# CC3200 register map
Vendor: Texas Instruments; Series: SimpleLink; File version: 1.0
CPU: CM4 r0p1, little endian, MPU, no FPU, 3 interrupt priority bits
Registers are 32-bit, read-write, reset 0x0 unless marked. A register's access mark holds for its fields unless they carry their own. Offsets are from the block's base; [hi:lo] are bit positions.

## HIB1P2
Base 0x4402F000
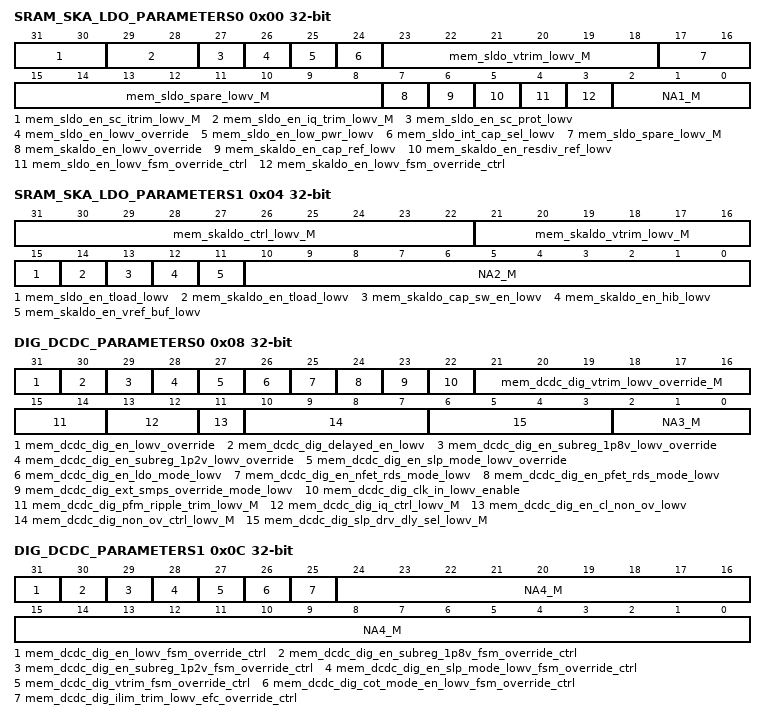
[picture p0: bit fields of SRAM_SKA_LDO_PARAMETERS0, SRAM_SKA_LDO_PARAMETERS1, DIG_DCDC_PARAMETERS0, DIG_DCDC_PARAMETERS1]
0x00 SRAM_SKA_LDO_PARAMETERS0 — HIB1P2_SRAM_SKA_LDO_PARAMETERS0
  [31:30] mem_sldo_en_sc_itrim_lowv_M — HIB1P2_SRAM_SKA_LDO_PARAMETERS0
  [29:28] mem_sldo_en_iq_trim_lowv_M — HIB1P2_SRAM_SKA_LDO_PARAMETERS0
  [27] mem_sldo_en_sc_prot_lowv — HIB1P2_SRAM_SKA_LDO_PARAMETERS0
  [26] mem_sldo_en_lowv_override — HIB1P2_SRAM_SKA_LDO_PARAMETERS0
  [25] mem_sldo_en_low_pwr_lowv — HIB1P2_SRAM_SKA_LDO_PARAMETERS0
  [24] mem_sldo_int_cap_sel_lowv — HIB1P2_SRAM_SKA_LDO_PARAMETERS0
  [23:18] mem_sldo_vtrim_lowv_M — HIB1P2_SRAM_SKA_LDO_PARAMETERS0
  [17:8] mem_sldo_spare_lowv_M — HIB1P2_SRAM_SKA_LDO_PARAMETERS0
  [7] mem_skaldo_en_lowv_override — HIB1P2_SRAM_SKA_LDO_PARAMETERS0
  [6] mem_skaldo_en_cap_ref_lowv — HIB1P2_SRAM_SKA_LDO_PARAMETERS0
  [5] mem_skaldo_en_resdiv_ref_lowv — HIB1P2_SRAM_SKA_LDO_PARAMETERS0
  [4] mem_sldo_en_lowv_fsm_override_ctrl — HIB1P2_SRAM_SKA_LDO_PARAMETERS0
  [3] mem_skaldo_en_lowv_fsm_override_ctrl — HIB1P2_SRAM_SKA_LDO_PARAMETERS0
  [2:0] NA1_M — HIB1P2_SRAM_SKA_LDO_PARAMETERS0
0x04 SRAM_SKA_LDO_PARAMETERS1 — HIB1P2_SRAM_SKA_LDO_PARAMETERS1
  [31:22] mem_skaldo_ctrl_lowv_M — HIB1P2_SRAM_SKA_LDO_PARAMETERS1
  [21:16] mem_skaldo_vtrim_lowv_M — HIB1P2_SRAM_SKA_LDO_PARAMETERS1
  [15] mem_sldo_en_tload_lowv — HIB1P2_SRAM_SKA_LDO_PARAMETERS1
  [14] mem_skaldo_en_tload_lowv — HIB1P2_SRAM_SKA_LDO_PARAMETERS1
  [13] mem_skaldo_cap_sw_en_lowv — HIB1P2_SRAM_SKA_LDO_PARAMETERS1
  [12] mem_skaldo_en_hib_lowv — HIB1P2_SRAM_SKA_LDO_PARAMETERS1
  [11] mem_skaldo_en_vref_buf_lowv — HIB1P2_SRAM_SKA_LDO_PARAMETERS1
  [10:0] NA2_M — HIB1P2_SRAM_SKA_LDO_PARAMETERS1
0x08 DIG_DCDC_PARAMETERS0 — HIB1P2_DIG_DCDC_PARAMETERS0
  [31] mem_dcdc_dig_en_lowv_override — HIB1P2_DIG_DCDC_PARAMETERS0
  [30] mem_dcdc_dig_delayed_en_lowv — HIB1P2_DIG_DCDC_PARAMETERS0
  [29] mem_dcdc_dig_en_subreg_1p8v_lowv_override — HIB1P2_DIG_DCDC_PARAMETERS0
  [28] mem_dcdc_dig_en_subreg_1p2v_lowv_override — HIB1P2_DIG_DCDC_PARAMETERS0
  [27] mem_dcdc_dig_en_slp_mode_lowv_override — HIB1P2_DIG_DCDC_PARAMETERS0
  [26] mem_dcdc_dig_en_ldo_mode_lowv — HIB1P2_DIG_DCDC_PARAMETERS0
  [25] mem_dcdc_dig_en_nfet_rds_mode_lowv — HIB1P2_DIG_DCDC_PARAMETERS0
  [24] mem_dcdc_dig_en_pfet_rds_mode_lowv — HIB1P2_DIG_DCDC_PARAMETERS0
  [23] mem_dcdc_dig_ext_smps_override_mode_lowv — HIB1P2_DIG_DCDC_PARAMETERS0
  [22] mem_dcdc_dig_clk_in_lowv_enable — HIB1P2_DIG_DCDC_PARAMETERS0
  [21:16] mem_dcdc_dig_vtrim_lowv_override_M — HIB1P2_DIG_DCDC_PARAMETERS0
  [15:14] mem_dcdc_dig_pfm_ripple_trim_lowv_M — HIB1P2_DIG_DCDC_PARAMETERS0
  [13:12] mem_dcdc_dig_iq_ctrl_lowv_M — HIB1P2_DIG_DCDC_PARAMETERS0
  [11] mem_dcdc_dig_en_cl_non_ov_lowv — HIB1P2_DIG_DCDC_PARAMETERS0
  [10:7] mem_dcdc_dig_non_ov_ctrl_lowv_M — HIB1P2_DIG_DCDC_PARAMETERS0
  [6:3] mem_dcdc_dig_slp_drv_dly_sel_lowv_M — HIB1P2_DIG_DCDC_PARAMETERS0
  [2:0] NA3_M — HIB1P2_DIG_DCDC_PARAMETERS0
0x0C DIG_DCDC_PARAMETERS1 — HIB1P2_DIG_DCDC_PARAMETERS1
  [31] mem_dcdc_dig_en_lowv_fsm_override_ctrl — HIB1P2_DIG_DCDC_PARAMETERS1
  [30] mem_dcdc_dig_en_subreg_1p8v_fsm_override_ctrl — HIB1P2_DIG_DCDC_PARAMETERS1
  [29] mem_dcdc_dig_en_subreg_1p2v_fsm_override_ctrl — HIB1P2_DIG_DCDC_PARAMETERS1
  [28] mem_dcdc_dig_en_slp_mode_lowv_fsm_override_ctrl — HIB1P2_DIG_DCDC_PARAMETERS1
  [27] mem_dcdc_dig_vtrim_fsm_override_ctrl — HIB1P2_DIG_DCDC_PARAMETERS1
  [26] mem_dcdc_dig_cot_mode_en_lowv_fsm_override_ctrl — HIB1P2_DIG_DCDC_PARAMETERS1
  [25] mem_dcdc_dig_ilim_trim_lowv_efc_override_ctrl — HIB1P2_DIG_DCDC_PARAMETERS1
  [24:0] NA4_M — HIB1P2_DIG_DCDC_PARAMETERS1
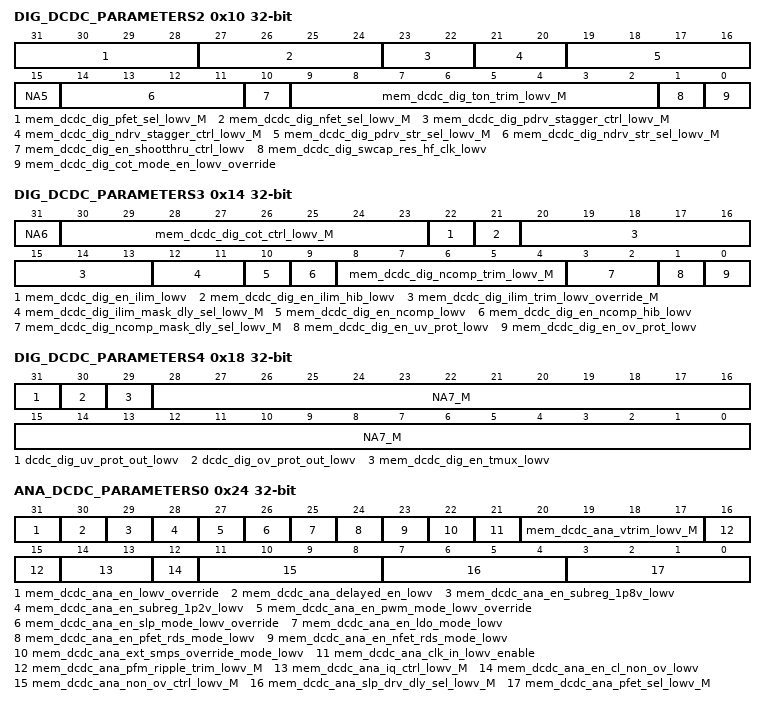
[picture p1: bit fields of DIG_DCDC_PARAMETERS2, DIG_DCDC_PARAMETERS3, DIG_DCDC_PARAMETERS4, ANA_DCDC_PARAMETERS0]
0x10 DIG_DCDC_PARAMETERS2 — HIB1P2_DIG_DCDC_PARAMETERS2
  [31:28] mem_dcdc_dig_pfet_sel_lowv_M — HIB1P2_DIG_DCDC_PARAMETERS2
  [27:24] mem_dcdc_dig_nfet_sel_lowv_M — HIB1P2_DIG_DCDC_PARAMETERS2
  [23:22] mem_dcdc_dig_pdrv_stagger_ctrl_lowv_M — HIB1P2_DIG_DCDC_PARAMETERS2
  [21:20] mem_dcdc_dig_ndrv_stagger_ctrl_lowv_M — HIB1P2_DIG_DCDC_PARAMETERS2
  [19:16] mem_dcdc_dig_pdrv_str_sel_lowv_M — HIB1P2_DIG_DCDC_PARAMETERS2
  [15] NA5 — HIB1P2_DIG_DCDC_PARAMETERS2
  [14:11] mem_dcdc_dig_ndrv_str_sel_lowv_M — HIB1P2_DIG_DCDC_PARAMETERS2
  [10] mem_dcdc_dig_en_shootthru_ctrl_lowv — HIB1P2_DIG_DCDC_PARAMETERS2
  [9:2] mem_dcdc_dig_ton_trim_lowv_M — HIB1P2_DIG_DCDC_PARAMETERS2
  [1] mem_dcdc_dig_swcap_res_hf_clk_lowv — HIB1P2_DIG_DCDC_PARAMETERS2
  [0] mem_dcdc_dig_cot_mode_en_lowv_override — HIB1P2_DIG_DCDC_PARAMETERS2
0x14 DIG_DCDC_PARAMETERS3 — HIB1P2_DIG_DCDC_PARAMETERS3
  [31] NA6 — HIB1P2_DIG_DCDC_PARAMETERS3
  [30:23] mem_dcdc_dig_cot_ctrl_lowv_M — HIB1P2_DIG_DCDC_PARAMETERS3
  [22] mem_dcdc_dig_en_ilim_lowv — HIB1P2_DIG_DCDC_PARAMETERS3
  [21] mem_dcdc_dig_en_ilim_hib_lowv — HIB1P2_DIG_DCDC_PARAMETERS3
  [20:13] mem_dcdc_dig_ilim_trim_lowv_override_M — HIB1P2_DIG_DCDC_PARAMETERS3
  [12:11] mem_dcdc_dig_ilim_mask_dly_sel_lowv_M — HIB1P2_DIG_DCDC_PARAMETERS3
  [10] mem_dcdc_dig_en_ncomp_lowv — HIB1P2_DIG_DCDC_PARAMETERS3
  [9] mem_dcdc_dig_en_ncomp_hib_lowv — HIB1P2_DIG_DCDC_PARAMETERS3
  [8:4] mem_dcdc_dig_ncomp_trim_lowv_M — HIB1P2_DIG_DCDC_PARAMETERS3
  [3:2] mem_dcdc_dig_ncomp_mask_dly_sel_lowv_M — HIB1P2_DIG_DCDC_PARAMETERS3
  [1] mem_dcdc_dig_en_uv_prot_lowv — HIB1P2_DIG_DCDC_PARAMETERS3
  [0] mem_dcdc_dig_en_ov_prot_lowv — HIB1P2_DIG_DCDC_PARAMETERS3
0x18 DIG_DCDC_PARAMETERS4 — HIB1P2_DIG_DCDC_PARAMETERS4
  [31] dcdc_dig_uv_prot_out_lowv — HIB1P2_DIG_DCDC_PARAMETERS4
  [30] dcdc_dig_ov_prot_out_lowv — HIB1P2_DIG_DCDC_PARAMETERS4
  [29] mem_dcdc_dig_en_tmux_lowv — HIB1P2_DIG_DCDC_PARAMETERS4
  [28:0] NA7_M — HIB1P2_DIG_DCDC_PARAMETERS4
0x1C DIG_DCDC_PARAMETERS5 — HIB1P2_DIG_DCDC_PARAMETERS5
  [31:0] mem_dcdc_dig_tmux_ctrl_lowv_M
0x20 DIG_DCDC_PARAMETERS6 — HIB1P2_DIG_DCDC_PARAMETERS6
  [31:0] mem_dcdc_dig_spare_lowv_M
0x24 ANA_DCDC_PARAMETERS0 — HIB1P2_ANA_DCDC_PARAMETERS0
  [31] mem_dcdc_ana_en_lowv_override — HIB1P2_ANA_DCDC_PARAMETERS0
  [30] mem_dcdc_ana_delayed_en_lowv — HIB1P2_ANA_DCDC_PARAMETERS0
  [29] mem_dcdc_ana_en_subreg_1p8v_lowv — HIB1P2_ANA_DCDC_PARAMETERS0
  [28] mem_dcdc_ana_en_subreg_1p2v_lowv — HIB1P2_ANA_DCDC_PARAMETERS0
  [27] mem_dcdc_ana_en_pwm_mode_lowv_override — HIB1P2_ANA_DCDC_PARAMETERS0
  [26] mem_dcdc_ana_en_slp_mode_lowv_override — HIB1P2_ANA_DCDC_PARAMETERS0
  [25] mem_dcdc_ana_en_ldo_mode_lowv — HIB1P2_ANA_DCDC_PARAMETERS0
  [24] mem_dcdc_ana_en_pfet_rds_mode_lowv — HIB1P2_ANA_DCDC_PARAMETERS0
  [23] mem_dcdc_ana_en_nfet_rds_mode_lowv — HIB1P2_ANA_DCDC_PARAMETERS0
  [22] mem_dcdc_ana_ext_smps_override_mode_lowv — HIB1P2_ANA_DCDC_PARAMETERS0
  [21] mem_dcdc_ana_clk_in_lowv_enable — HIB1P2_ANA_DCDC_PARAMETERS0
  [20:17] mem_dcdc_ana_vtrim_lowv_M — HIB1P2_ANA_DCDC_PARAMETERS0
  [16:15] mem_dcdc_ana_pfm_ripple_trim_lowv_M — HIB1P2_ANA_DCDC_PARAMETERS0
  [14:13] mem_dcdc_ana_iq_ctrl_lowv_M — HIB1P2_ANA_DCDC_PARAMETERS0
  [12] mem_dcdc_ana_en_cl_non_ov_lowv — HIB1P2_ANA_DCDC_PARAMETERS0
  [11:8] mem_dcdc_ana_non_ov_ctrl_lowv_M — HIB1P2_ANA_DCDC_PARAMETERS0
  [7:4] mem_dcdc_ana_slp_drv_dly_sel_lowv_M — HIB1P2_ANA_DCDC_PARAMETERS0
  [3:0] mem_dcdc_ana_pfet_sel_lowv_M — HIB1P2_ANA_DCDC_PARAMETERS0
0x28 ANA_DCDC_PARAMETERS1 — HIB1P2_ANA_DCDC_PARAMETERS1
  [31] _dcdc_ana_ov_prot_out_lowv — HIB1P2_ANA_DCDC_PARAMETERS1
  [30] _mem_dcdc_ana_en_tmux_lowv — HIB1P2_ANA_DCDC_PARAMETERS1
  [31:28] mem_dcdc_ana_nfet_sel_lowv_M — HIB1P2_ANA_DCDC_PARAMETERS1
  [27:26] mem_dcdc_ana_pdrv_stagger_ctrl_lowv_M — HIB1P2_ANA_DCDC_PARAMETERS1
  [25:24] mem_dcdc_ana_ndrv_stagger_ctrl_lowv_M — HIB1P2_ANA_DCDC_PARAMETERS1
  [21] _mem_dcdc_ana_en_ilim_lowv — HIB1P2_ANA_DCDC_PARAMETERS1
  [23:20] mem_dcdc_ana_pdrv_str_sel_lowv_M — HIB1P2_ANA_DCDC_PARAMETERS1
  [20] _mem_dcdc_ana_en_ilim_hib_lowv — HIB1P2_ANA_DCDC_PARAMETERS1
  [19:16] mem_dcdc_ana_ndrv_str_sel_lowv_M — HIB1P2_ANA_DCDC_PARAMETERS1
  [15] mem_dcdc_ana_en_rtrim_lowv — HIB1P2_ANA_DCDC_PARAMETERS1
  [14] mem_dcdc_ana_apwm_en_lowv — HIB1P2_ANA_DCDC_PARAMETERS1
  [19:12] _mem_dcdc_ana_ilim_trim_lowv_override_M — HIB1P2_ANA_DCDC_PARAMETERS1
  [11:10] _mem_dcdc_ana_ilim_mask_dly_sel_lowv_M — HIB1P2_ANA_DCDC_PARAMETERS1
  [13:9] mem_dcdc_ana_ramp_hgt_lowv_M — HIB1P2_ANA_DCDC_PARAMETERS1
  [9] _mem_dcdc_ana_en_ncomp_lowv — HIB1P2_ANA_DCDC_PARAMETERS1
  [8] mem_dcdc_ana_en_anti_glitch_lowv — HIB1P2_ANA_DCDC_PARAMETERS1
  [8] _mem_dcdc_ana_en_ncomp_hib_lowv — HIB1P2_ANA_DCDC_PARAMETERS1
  [7] mem_dcdc_ana_en_hi_clamp_lowv — HIB1P2_ANA_DCDC_PARAMETERS1
  [6:5] mem_dcdc_ana_hi_clamp_trim_lowv_M — HIB1P2_ANA_DCDC_PARAMETERS1
  [4] mem_dcdc_ana_en_lo_clamp_lowv — HIB1P2_ANA_DCDC_PARAMETERS1
  [7:3] _mem_dcdc_ana_ncomp_trim_lowv_M — HIB1P2_ANA_DCDC_PARAMETERS1
  [3:2] mem_dcdc_ana_lo_clamp_trim_lowv_M — HIB1P2_ANA_DCDC_PARAMETERS1
  [2:1] _mem_dcdc_ana_ncomp_mask_dly_sel_lowv_M — HIB1P2_ANA_DCDC_PARAMETERS1
  [1:0] NA8_M — HIB1P2_ANA_DCDC_PARAMETERS1
  [0] _mem_dcdc_ana_en_ov_prot_lowv — HIB1P2_ANA_DCDC_PARAMETERS1
  [29:0] _NA17_M — HIB1P2_ANA_DCDC_PARAMETERS1
  [31:0] _mem_dcdc_ana_tmux_ctrl_lowv_M — HIB1P2_ANA_DCDC_PARAMETERS1
  [31:0] _mem_dcdc_ana_spare_lowv_M — HIB1P2_ANA_DCDC_PARAMETERS1
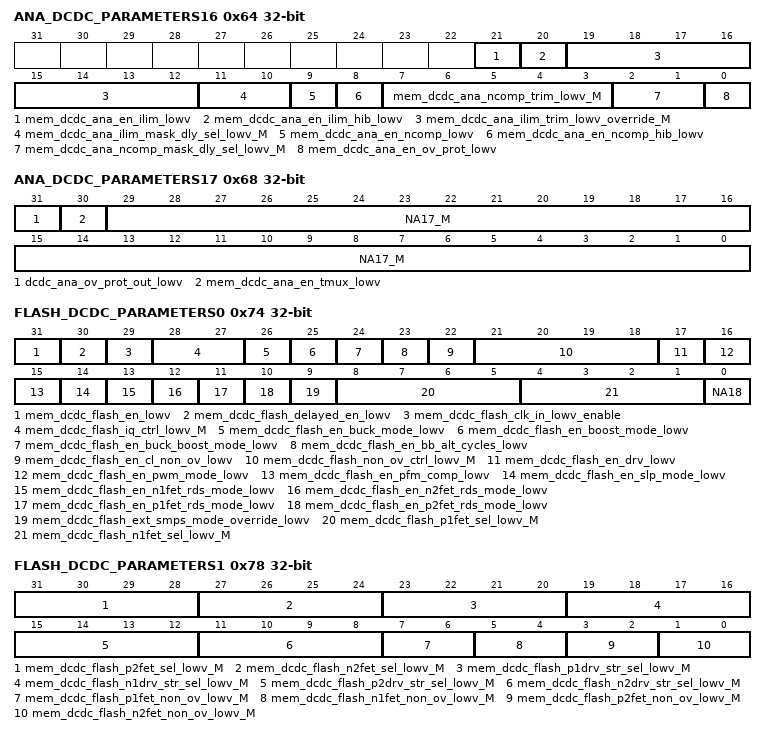
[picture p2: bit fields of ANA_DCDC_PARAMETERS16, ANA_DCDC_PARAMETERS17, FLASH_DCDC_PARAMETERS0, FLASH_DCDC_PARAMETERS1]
0x64 ANA_DCDC_PARAMETERS16 — HIB1P2_ANA_DCDC_PARAMETERS16
  [21] mem_dcdc_ana_en_ilim_lowv — HIB1P2_ANA_DCDC_PARAMETERS16
  [20] mem_dcdc_ana_en_ilim_hib_lowv — HIB1P2_ANA_DCDC_PARAMETERS16
  [19:12] mem_dcdc_ana_ilim_trim_lowv_override_M — HIB1P2_ANA_DCDC_PARAMETERS16
  [11:10] mem_dcdc_ana_ilim_mask_dly_sel_lowv_M — HIB1P2_ANA_DCDC_PARAMETERS16
  [9] mem_dcdc_ana_en_ncomp_lowv — HIB1P2_ANA_DCDC_PARAMETERS16
  [8] mem_dcdc_ana_en_ncomp_hib_lowv — HIB1P2_ANA_DCDC_PARAMETERS16
  [7:3] mem_dcdc_ana_ncomp_trim_lowv_M — HIB1P2_ANA_DCDC_PARAMETERS16
  [2:1] mem_dcdc_ana_ncomp_mask_dly_sel_lowv_M — HIB1P2_ANA_DCDC_PARAMETERS16
  [0] mem_dcdc_ana_en_ov_prot_lowv — HIB1P2_ANA_DCDC_PARAMETERS16
0x68 ANA_DCDC_PARAMETERS17 — HIB1P2_ANA_DCDC_PARAMETERS17
  [31] dcdc_ana_ov_prot_out_lowv — HIB1P2_ANA_DCDC_PARAMETERS17
  [30] mem_dcdc_ana_en_tmux_lowv — HIB1P2_ANA_DCDC_PARAMETERS17
  [29:0] NA17_M — HIB1P2_ANA_DCDC_PARAMETERS17
0x6C ANA_DCDC_PARAMETERS18 — HIB1P2_ANA_DCDC_PARAMETERS18
  [31:0] mem_dcdc_ana_tmux_ctrl_lowv_M
0x70 ANA_DCDC_PARAMETERS19 — HIB1P2_ANA_DCDC_PARAMETERS19
  [31:0] mem_dcdc_ana_spare_lowv_M
0x74 FLASH_DCDC_PARAMETERS0 — HIB1P2_FLASH_DCDC_PARAMETERS0
  [31] mem_dcdc_flash_en_lowv — HIB1P2_FLASH_DCDC_PARAMETERS0
  [30] mem_dcdc_flash_delayed_en_lowv — HIB1P2_FLASH_DCDC_PARAMETERS0
  [29] mem_dcdc_flash_clk_in_lowv_enable — HIB1P2_FLASH_DCDC_PARAMETERS0
  [28:27] mem_dcdc_flash_iq_ctrl_lowv_M — HIB1P2_FLASH_DCDC_PARAMETERS0
  [26] mem_dcdc_flash_en_buck_mode_lowv — HIB1P2_FLASH_DCDC_PARAMETERS0
  [25] mem_dcdc_flash_en_boost_mode_lowv — HIB1P2_FLASH_DCDC_PARAMETERS0
  [24] mem_dcdc_flash_en_buck_boost_mode_lowv — HIB1P2_FLASH_DCDC_PARAMETERS0
  [23] mem_dcdc_flash_en_bb_alt_cycles_lowv — HIB1P2_FLASH_DCDC_PARAMETERS0
  [22] mem_dcdc_flash_en_cl_non_ov_lowv — HIB1P2_FLASH_DCDC_PARAMETERS0
  [21:18] mem_dcdc_flash_non_ov_ctrl_lowv_M — HIB1P2_FLASH_DCDC_PARAMETERS0
  [17] mem_dcdc_flash_en_drv_lowv — HIB1P2_FLASH_DCDC_PARAMETERS0
  [16] mem_dcdc_flash_en_pwm_mode_lowv — HIB1P2_FLASH_DCDC_PARAMETERS0
  [15] mem_dcdc_flash_en_pfm_comp_lowv — HIB1P2_FLASH_DCDC_PARAMETERS0
  [14] mem_dcdc_flash_en_slp_mode_lowv — HIB1P2_FLASH_DCDC_PARAMETERS0
  [13] mem_dcdc_flash_en_n1fet_rds_mode_lowv — HIB1P2_FLASH_DCDC_PARAMETERS0
  [12] mem_dcdc_flash_en_n2fet_rds_mode_lowv — HIB1P2_FLASH_DCDC_PARAMETERS0
  [11] mem_dcdc_flash_en_p1fet_rds_mode_lowv — HIB1P2_FLASH_DCDC_PARAMETERS0
  [10] mem_dcdc_flash_en_p2fet_rds_mode_lowv — HIB1P2_FLASH_DCDC_PARAMETERS0
  [9] mem_dcdc_flash_ext_smps_mode_override_lowv — HIB1P2_FLASH_DCDC_PARAMETERS0
  [8:5] mem_dcdc_flash_p1fet_sel_lowv_M — HIB1P2_FLASH_DCDC_PARAMETERS0
  [4:1] mem_dcdc_flash_n1fet_sel_lowv_M — HIB1P2_FLASH_DCDC_PARAMETERS0
  [0] NA18 — HIB1P2_FLASH_DCDC_PARAMETERS0
0x78 FLASH_DCDC_PARAMETERS1 — HIB1P2_FLASH_DCDC_PARAMETERS1
  [31:28] mem_dcdc_flash_p2fet_sel_lowv_M — HIB1P2_FLASH_DCDC_PARAMETERS1
  [27:24] mem_dcdc_flash_n2fet_sel_lowv_M — HIB1P2_FLASH_DCDC_PARAMETERS1
  [23:20] mem_dcdc_flash_p1drv_str_sel_lowv_M — HIB1P2_FLASH_DCDC_PARAMETERS1
  [19:16] mem_dcdc_flash_n1drv_str_sel_lowv_M — HIB1P2_FLASH_DCDC_PARAMETERS1
  [15:12] mem_dcdc_flash_p2drv_str_sel_lowv_M — HIB1P2_FLASH_DCDC_PARAMETERS1
  [11:8] mem_dcdc_flash_n2drv_str_sel_lowv_M — HIB1P2_FLASH_DCDC_PARAMETERS1
  [7:6] mem_dcdc_flash_p1fet_non_ov_lowv_M — HIB1P2_FLASH_DCDC_PARAMETERS1
  [5:4] mem_dcdc_flash_n1fet_non_ov_lowv_M — HIB1P2_FLASH_DCDC_PARAMETERS1
  [3:2] mem_dcdc_flash_p2fet_non_ov_lowv_M — HIB1P2_FLASH_DCDC_PARAMETERS1
  [1:0] mem_dcdc_flash_n2fet_non_ov_lowv_M — HIB1P2_FLASH_DCDC_PARAMETERS1
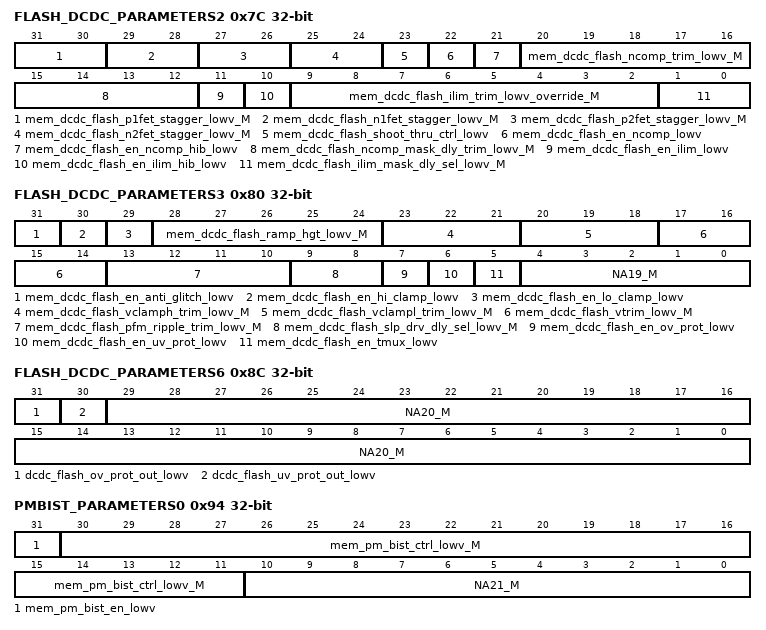
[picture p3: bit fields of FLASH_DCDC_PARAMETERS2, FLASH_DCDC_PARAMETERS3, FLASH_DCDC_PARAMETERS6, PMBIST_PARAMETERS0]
0x7C FLASH_DCDC_PARAMETERS2 — HIB1P2_FLASH_DCDC_PARAMETERS2
  [31:30] mem_dcdc_flash_p1fet_stagger_lowv_M — HIB1P2_FLASH_DCDC_PARAMETERS2
  [29:28] mem_dcdc_flash_n1fet_stagger_lowv_M — HIB1P2_FLASH_DCDC_PARAMETERS2
  [27:26] mem_dcdc_flash_p2fet_stagger_lowv_M — HIB1P2_FLASH_DCDC_PARAMETERS2
  [25:24] mem_dcdc_flash_n2fet_stagger_lowv_M — HIB1P2_FLASH_DCDC_PARAMETERS2
  [23] mem_dcdc_flash_shoot_thru_ctrl_lowv — HIB1P2_FLASH_DCDC_PARAMETERS2
  [22] mem_dcdc_flash_en_ncomp_lowv — HIB1P2_FLASH_DCDC_PARAMETERS2
  [21] mem_dcdc_flash_en_ncomp_hib_lowv — HIB1P2_FLASH_DCDC_PARAMETERS2
  [20:16] mem_dcdc_flash_ncomp_trim_lowv_M — HIB1P2_FLASH_DCDC_PARAMETERS2
  [15:12] mem_dcdc_flash_ncomp_mask_dly_trim_lowv_M — HIB1P2_FLASH_DCDC_PARAMETERS2
  [11] mem_dcdc_flash_en_ilim_lowv — HIB1P2_FLASH_DCDC_PARAMETERS2
  [10] mem_dcdc_flash_en_ilim_hib_lowv — HIB1P2_FLASH_DCDC_PARAMETERS2
  [9:2] mem_dcdc_flash_ilim_trim_lowv_override_M — HIB1P2_FLASH_DCDC_PARAMETERS2
  [1:0] mem_dcdc_flash_ilim_mask_dly_sel_lowv_M — HIB1P2_FLASH_DCDC_PARAMETERS2
0x80 FLASH_DCDC_PARAMETERS3 — HIB1P2_FLASH_DCDC_PARAMETERS3
  [31] mem_dcdc_flash_en_anti_glitch_lowv — HIB1P2_FLASH_DCDC_PARAMETERS3
  [30] mem_dcdc_flash_en_hi_clamp_lowv — HIB1P2_FLASH_DCDC_PARAMETERS3
  [29] mem_dcdc_flash_en_lo_clamp_lowv — HIB1P2_FLASH_DCDC_PARAMETERS3
  [28:24] mem_dcdc_flash_ramp_hgt_lowv_M — HIB1P2_FLASH_DCDC_PARAMETERS3
  [23:21] mem_dcdc_flash_vclamph_trim_lowv_M — HIB1P2_FLASH_DCDC_PARAMETERS3
  [20:18] mem_dcdc_flash_vclampl_trim_lowv_M — HIB1P2_FLASH_DCDC_PARAMETERS3
  [17:14] mem_dcdc_flash_vtrim_lowv_M — HIB1P2_FLASH_DCDC_PARAMETERS3
  [13:10] mem_dcdc_flash_pfm_ripple_trim_lowv_M — HIB1P2_FLASH_DCDC_PARAMETERS3
  [9:8] mem_dcdc_flash_slp_drv_dly_sel_lowv_M — HIB1P2_FLASH_DCDC_PARAMETERS3
  [7] mem_dcdc_flash_en_ov_prot_lowv — HIB1P2_FLASH_DCDC_PARAMETERS3
  [6] mem_dcdc_flash_en_uv_prot_lowv — HIB1P2_FLASH_DCDC_PARAMETERS3
  [5] mem_dcdc_flash_en_tmux_lowv — HIB1P2_FLASH_DCDC_PARAMETERS3
  [4:0] NA19_M — HIB1P2_FLASH_DCDC_PARAMETERS3
0x84 FLASH_DCDC_PARAMETERS4 — HIB1P2_FLASH_DCDC_PARAMETERS4
  [31:0] mem_dcdc_flash_tmux_ctrl_lowv_M
0x88 FLASH_DCDC_PARAMETERS5 — HIB1P2_FLASH_DCDC_PARAMETERS5
  [31:0] mem_dcdc_flash_spare_lowv_M
0x8C FLASH_DCDC_PARAMETERS6 — HIB1P2_FLASH_DCDC_PARAMETERS6
  [31] dcdc_flash_ov_prot_out_lowv — HIB1P2_FLASH_DCDC_PARAMETERS6
  [30] dcdc_flash_uv_prot_out_lowv — HIB1P2_FLASH_DCDC_PARAMETERS6
  [29:0] NA20_M — HIB1P2_FLASH_DCDC_PARAMETERS6
0x94 PMBIST_PARAMETERS0 — HIB1P2_PMBIST_PARAMETERS0
  [31] mem_pm_bist_en_lowv — HIB1P2_PMBIST_PARAMETERS0
  [30:11] mem_pm_bist_ctrl_lowv_M — HIB1P2_PMBIST_PARAMETERS0
  [10:0] NA21_M — HIB1P2_PMBIST_PARAMETERS0
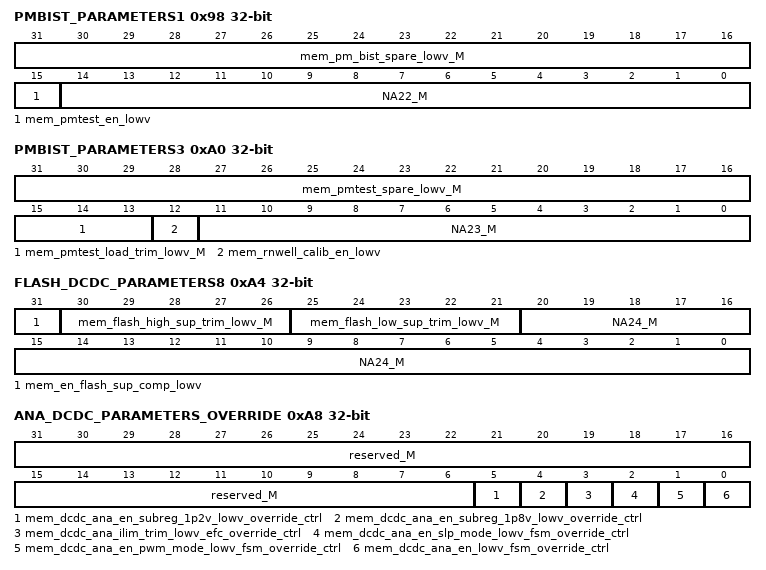
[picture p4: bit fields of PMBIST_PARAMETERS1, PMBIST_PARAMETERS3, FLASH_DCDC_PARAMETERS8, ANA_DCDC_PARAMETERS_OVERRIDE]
0x98 PMBIST_PARAMETERS1 — HIB1P2_PMBIST_PARAMETERS1
  [31:16] mem_pm_bist_spare_lowv_M — HIB1P2_PMBIST_PARAMETERS1
  [15] mem_pmtest_en_lowv — HIB1P2_PMBIST_PARAMETERS1
  [14:0] NA22_M — HIB1P2_PMBIST_PARAMETERS1
0x9C PMBIST_PARAMETERS2 — HIB1P2_PMBIST_PARAMETERS2
  [31:0] mem_pmtest_tmux_ctrl_lowv_M
0xA0 PMBIST_PARAMETERS3 — HIB1P2_PMBIST_PARAMETERS3
  [31:16] mem_pmtest_spare_lowv_M — HIB1P2_PMBIST_PARAMETERS3
  [15:13] mem_pmtest_load_trim_lowv_M — HIB1P2_PMBIST_PARAMETERS3
  [12] mem_rnwell_calib_en_lowv — HIB1P2_PMBIST_PARAMETERS3
  [11:0] NA23_M — HIB1P2_PMBIST_PARAMETERS3
0xA4 FLASH_DCDC_PARAMETERS8 — HIB1P2_FLASH_DCDC_PARAMETERS8
  [31] mem_en_flash_sup_comp_lowv — HIB1P2_FLASH_DCDC_PARAMETERS8
  [30:26] mem_flash_high_sup_trim_lowv_M — HIB1P2_FLASH_DCDC_PARAMETERS8
  [25:21] mem_flash_low_sup_trim_lowv_M — HIB1P2_FLASH_DCDC_PARAMETERS8
  [20:0] NA24_M — HIB1P2_FLASH_DCDC_PARAMETERS8
0xA8 ANA_DCDC_PARAMETERS_OVERRIDE — HIB1P2_ANA_DCDC_PARAMETERS_OVERRIDE
  [31:6] reserved_M — HIB1P2_ANA_DCDC_PARAMETERS_OVERRIDE
  [5] mem_dcdc_ana_en_subreg_1p2v_lowv_override_ctrl — HIB1P2_ANA_DCDC_PARAMETERS_OVERRIDE
  [4] mem_dcdc_ana_en_subreg_1p8v_lowv_override_ctrl — HIB1P2_ANA_DCDC_PARAMETERS_OVERRIDE
  [3] mem_dcdc_ana_ilim_trim_lowv_efc_override_ctrl — HIB1P2_ANA_DCDC_PARAMETERS_OVERRIDE
  [2] mem_dcdc_ana_en_slp_mode_lowv_fsm_override_ctrl — HIB1P2_ANA_DCDC_PARAMETERS_OVERRIDE
  [1] mem_dcdc_ana_en_pwm_mode_lowv_fsm_override_ctrl — HIB1P2_ANA_DCDC_PARAMETERS_OVERRIDE
  [0] mem_dcdc_ana_en_lowv_fsm_override_ctrl — HIB1P2_ANA_DCDC_PARAMETERS_OVERRIDE
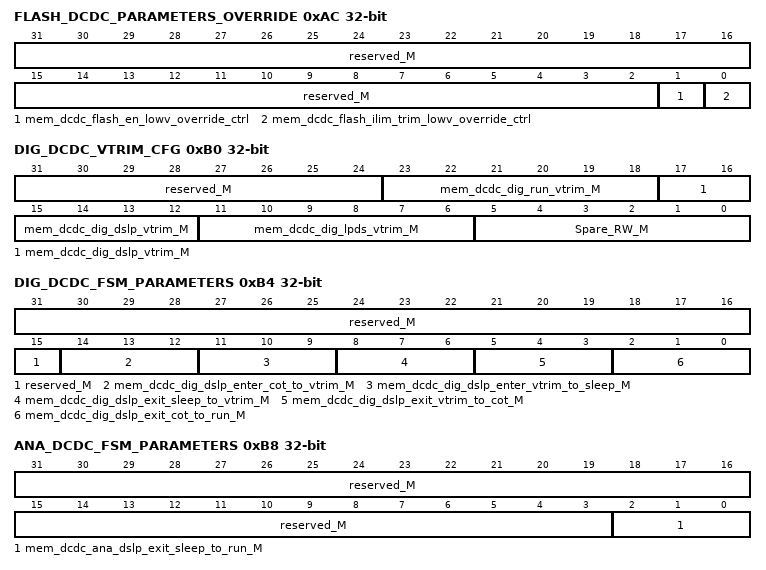
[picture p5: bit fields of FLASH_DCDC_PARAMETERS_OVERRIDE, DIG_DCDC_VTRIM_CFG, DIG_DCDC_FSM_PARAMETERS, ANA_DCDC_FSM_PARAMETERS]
0xAC FLASH_DCDC_PARAMETERS_OVERRIDE — HIB1P2_FLASH_DCDC_PARAMETERS_OVERRIDE
  [31:2] reserved_M — HIB1P2_FLASH_DCDC_PARAMETERS_OVERRIDE
  [1] mem_dcdc_flash_en_lowv_override_ctrl — HIB1P2_FLASH_DCDC_PARAMETERS_OVERRIDE
  [0] mem_dcdc_flash_ilim_trim_lowv_override_ctrl — HIB1P2_FLASH_DCDC_PARAMETERS_OVERRIDE
0xB0 DIG_DCDC_VTRIM_CFG — HIB1P2_DIG_DCDC_VTRIM_CFG
  [31:24] reserved_M — HIB1P2_DIG_DCDC_VTRIM_CFG
  [23:18] mem_dcdc_dig_run_vtrim_M — HIB1P2_DIG_DCDC_VTRIM_CFG
  [17:12] mem_dcdc_dig_dslp_vtrim_M — HIB1P2_DIG_DCDC_VTRIM_CFG
  [11:6] mem_dcdc_dig_lpds_vtrim_M — HIB1P2_DIG_DCDC_VTRIM_CFG
  [5:0] Spare_RW_M — HIB1P2_DIG_DCDC_VTRIM_CFG
0xB4 DIG_DCDC_FSM_PARAMETERS — HIB1P2_DIG_DCDC_FSM_PARAMETERS
  [31:15] reserved_M — HIB1P2_DIG_DCDC_FSM_PARAMETERS
  [14:12] mem_dcdc_dig_dslp_enter_cot_to_vtrim_M — HIB1P2_DIG_DCDC_FSM_PARAMETERS
  [11:9] mem_dcdc_dig_dslp_enter_vtrim_to_sleep_M — HIB1P2_DIG_DCDC_FSM_PARAMETERS
  [8:6] mem_dcdc_dig_dslp_exit_sleep_to_vtrim_M — HIB1P2_DIG_DCDC_FSM_PARAMETERS
  [5:3] mem_dcdc_dig_dslp_exit_vtrim_to_cot_M — HIB1P2_DIG_DCDC_FSM_PARAMETERS
  [2:0] mem_dcdc_dig_dslp_exit_cot_to_run_M — HIB1P2_DIG_DCDC_FSM_PARAMETERS
0xB8 ANA_DCDC_FSM_PARAMETERS — HIB1P2_ANA_DCDC_FSM_PARAMETERS
  [31:3] reserved_M — HIB1P2_ANA_DCDC_FSM_PARAMETERS
  [2:0] mem_dcdc_ana_dslp_exit_sleep_to_run_M — HIB1P2_ANA_DCDC_FSM_PARAMETERS
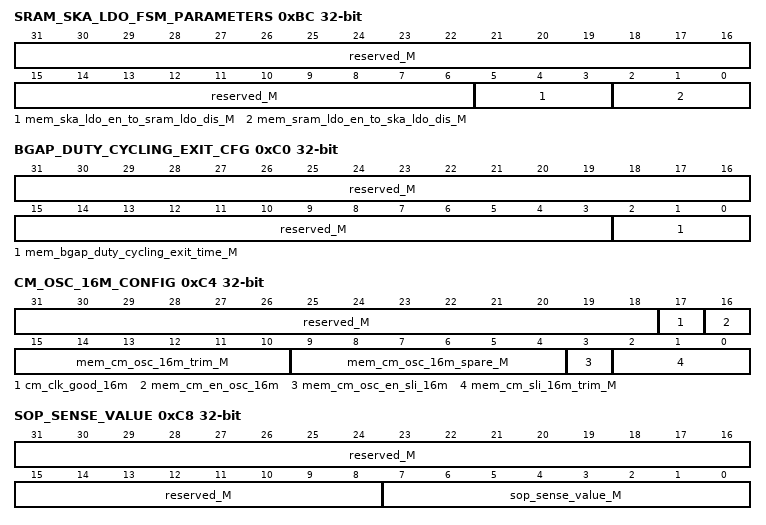
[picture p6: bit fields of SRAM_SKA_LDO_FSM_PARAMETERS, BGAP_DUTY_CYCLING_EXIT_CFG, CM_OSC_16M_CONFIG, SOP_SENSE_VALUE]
0xBC SRAM_SKA_LDO_FSM_PARAMETERS — HIB1P2_SRAM_SKA_LDO_FSM_PARAMETERS
  [31:6] reserved_M — HIB1P2_SRAM_SKA_LDO_FSM_PARAMETERS
  [5:3] mem_ska_ldo_en_to_sram_ldo_dis_M — HIB1P2_SRAM_SKA_LDO_FSM_PARAMETERS
  [2:0] mem_sram_ldo_en_to_ska_ldo_dis_M — HIB1P2_SRAM_SKA_LDO_FSM_PARAMETERS
0xC0 BGAP_DUTY_CYCLING_EXIT_CFG — HIB1P2_BGAP_DUTY_CYCLING_EXIT_CFG
  [31:3] reserved_M — HIB1P2_BGAP_DUTY_CYCLING_EXIT_CFG
  [2:0] mem_bgap_duty_cycling_exit_time_M — HIB1P2_BGAP_DUTY_CYCLING_EXIT_CFG
0xC4 CM_OSC_16M_CONFIG — HIB1P2_CM_OSC_16M_CONFIG
  [31:18] reserved_M — HIB1P2_CM_OSC_16M_CONFIG
  [17] cm_clk_good_16m — HIB1P2_CM_OSC_16M_CONFIG
  [16] mem_cm_en_osc_16m — HIB1P2_CM_OSC_16M_CONFIG
  [15:10] mem_cm_osc_16m_trim_M — HIB1P2_CM_OSC_16M_CONFIG
  [9:4] mem_cm_osc_16m_spare_M — HIB1P2_CM_OSC_16M_CONFIG
  [3] mem_cm_osc_en_sli_16m — HIB1P2_CM_OSC_16M_CONFIG
  [2:0] mem_cm_sli_16m_trim_M — HIB1P2_CM_OSC_16M_CONFIG
0xC8 SOP_SENSE_VALUE — HIB1P2_SOP_SENSE_VALUE
  [31:8] reserved_M — HIB1P2_SOP_SENSE_VALUE
  [7:0] sop_sense_value_M — HIB1P2_SOP_SENSE_VALUE
0xCC HIB_RTC_TIMER_LSW_1P2 — HIB1P2_HIB_RTC_TIMER_LSW_1P2
  [31:0] hib_rtc_timer_lsw_M
0xD0 HIB_RTC_TIMER_MSW_1P2 — HIB1P2_HIB_RTC_TIMER_MSW_1P2
  [15:0] hib_rtc_timer_msw_M
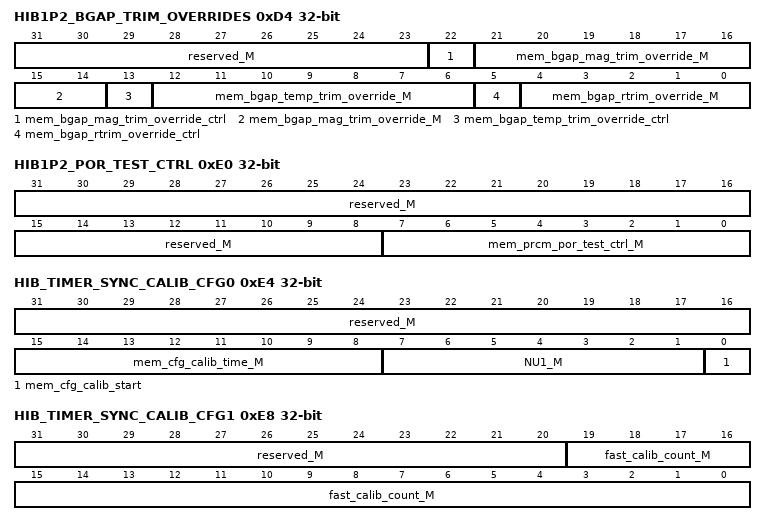
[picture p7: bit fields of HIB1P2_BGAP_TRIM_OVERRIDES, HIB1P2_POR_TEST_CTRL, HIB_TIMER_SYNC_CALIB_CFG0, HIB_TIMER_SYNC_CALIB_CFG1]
0xD4 HIB1P2_BGAP_TRIM_OVERRIDES — HIB1P2_HIB1P2_BGAP_TRIM_OVERRIDES
  [31:23] reserved_M — HIB1P2_HIB1P2_BGAP_TRIM_OVERRIDES
  [22] mem_bgap_mag_trim_override_ctrl — HIB1P2_HIB1P2_BGAP_TRIM_OVERRIDES
  [21:14] mem_bgap_mag_trim_override_M — HIB1P2_HIB1P2_BGAP_TRIM_OVERRIDES
  [13] mem_bgap_temp_trim_override_ctrl — HIB1P2_HIB1P2_BGAP_TRIM_OVERRIDES
  [12:6] mem_bgap_temp_trim_override_M — HIB1P2_HIB1P2_BGAP_TRIM_OVERRIDES
  [5] mem_bgap_rtrim_override_ctrl — HIB1P2_HIB1P2_BGAP_TRIM_OVERRIDES
  [4:0] mem_bgap_rtrim_override_M — HIB1P2_HIB1P2_BGAP_TRIM_OVERRIDES
0xD8 HIB1P2_EFUSE_READ_REG0 — HIB1P2_HIB1P2_EFUSE_READ_REG0
  [31:0] FUSEFARM_ROW_12_M
0xDC HIB1P2_EFUSE_READ_REG1 — HIB1P2_HIB1P2_EFUSE_READ_REG1
  [31:0] FUSEFARM_ROW_13_M
0xE0 HIB1P2_POR_TEST_CTRL — HIB1P2_HIB1P2_POR_TEST_CTRL
  [31:8] reserved_M — HIB1P2_HIB1P2_POR_TEST_CTRL
  [7:0] mem_prcm_por_test_ctrl_M — HIB1P2_HIB1P2_POR_TEST_CTRL
0xE4 HIB_TIMER_SYNC_CALIB_CFG0 — HIB1P2_HIB_TIMER_SYNC_CALIB_CFG0
  [31:16] reserved_M — HIB1P2_HIB_TIMER_SYNC_CALIB_CFG0
  [15:8] mem_cfg_calib_time_M — HIB1P2_HIB_TIMER_SYNC_CALIB_CFG0
  [7:1] NU1_M — HIB1P2_HIB_TIMER_SYNC_CALIB_CFG0
  [0] mem_cfg_calib_start — HIB1P2_HIB_TIMER_SYNC_CALIB_CFG0
0xE8 HIB_TIMER_SYNC_CALIB_CFG1 — HIB1P2_HIB_TIMER_SYNC_CALIB_CFG1
  [31:20] reserved_M — HIB1P2_HIB_TIMER_SYNC_CALIB_CFG1
  [19:0] fast_calib_count_M — HIB1P2_HIB_TIMER_SYNC_CALIB_CFG1
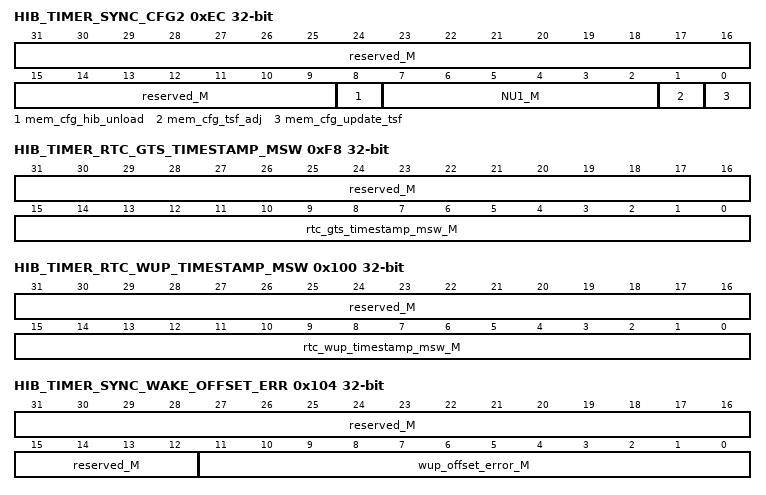
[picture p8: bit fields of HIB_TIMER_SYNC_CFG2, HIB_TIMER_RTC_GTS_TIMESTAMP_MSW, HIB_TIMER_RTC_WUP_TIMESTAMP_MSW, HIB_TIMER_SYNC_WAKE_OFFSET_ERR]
0xEC HIB_TIMER_SYNC_CFG2 — HIB1P2_HIB_TIMER_SYNC_CFG2
  [31:9] reserved_M — HIB1P2_HIB_TIMER_SYNC_CFG2
  [8] mem_cfg_hib_unload — HIB1P2_HIB_TIMER_SYNC_CFG2
  [7:2] NU1_M — HIB1P2_HIB_TIMER_SYNC_CFG2
  [1] mem_cfg_tsf_adj — HIB1P2_HIB_TIMER_SYNC_CFG2
  [0] mem_cfg_update_tsf — HIB1P2_HIB_TIMER_SYNC_CFG2
0xF0 HIB_TIMER_SYNC_TSF_ADJ_VAL — HIB1P2_HIB_TIMER_SYNC_TSF_ADJ_VAL
  [31:0] mem_tsf_adj_val_M
0xF4 HIB_TIMER_RTC_GTS_TIMESTAMP_LSW — HIB1P2_HIB_TIMER_RTC_GTS_TIMESTAMP_LSW
  [31:0] rtc_gts_timestamp_lsw_M
0xF8 HIB_TIMER_RTC_GTS_TIMESTAMP_MSW — HIB1P2_HIB_TIMER_RTC_GTS_TIMESTAMP_MSW
  [31:16] reserved_M — HIB1P2_HIB_TIMER_RTC_GTS_TIMESTAMP_MSW
  [15:0] rtc_gts_timestamp_msw_M — HIB1P2_HIB_TIMER_RTC_GTS_TIMESTAMP_MSW
0xFC HIB_TIMER_RTC_WUP_TIMESTAMP_LSW — HIB1P2_HIB_TIMER_RTC_WUP_TIMESTAMP_LSW
  [31:0] rtc_wup_timestamp_lsw_M
0x100 HIB_TIMER_RTC_WUP_TIMESTAMP_MSW — HIB1P2_HIB_TIMER_RTC_WUP_TIMESTAMP_MSW
  [31:16] reserved_M — HIB1P2_HIB_TIMER_RTC_WUP_TIMESTAMP_MSW
  [15:0] rtc_wup_timestamp_msw_M — HIB1P2_HIB_TIMER_RTC_WUP_TIMESTAMP_MSW
0x104 HIB_TIMER_SYNC_WAKE_OFFSET_ERR — HIB1P2_HIB_TIMER_SYNC_WAKE_OFFSET_ERR
  [31:12] reserved_M — HIB1P2_HIB_TIMER_SYNC_WAKE_OFFSET_ERR
  [11:0] wup_offset_error_M — HIB1P2_HIB_TIMER_SYNC_WAKE_OFFSET_ERR
0x108 HIB_TIMER_SYNC_TSF_CURR_VAL_LSW — HIB1P2_HIB_TIMER_SYNC_TSF_CURR_VAL_LSW
  [31:0] tsf_curr_val_lsw_M
0x10C HIB_TIMER_SYNC_TSF_CURR_VAL_MSW — HIB1P2_HIB_TIMER_SYNC_TSF_CURR_VAL_MSW
  [31:0] tsf_curr_val_msw_M
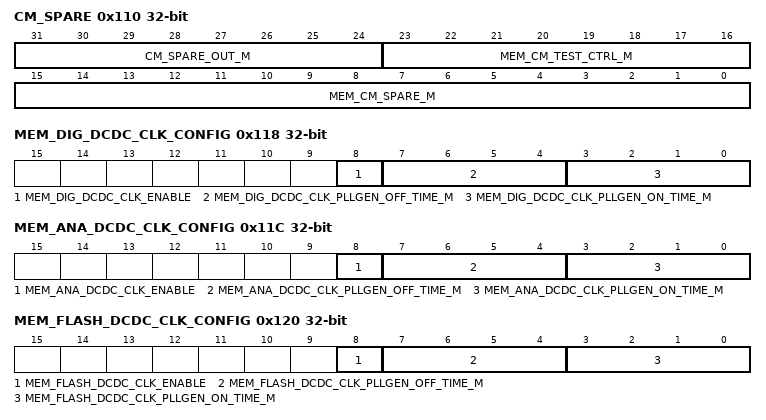
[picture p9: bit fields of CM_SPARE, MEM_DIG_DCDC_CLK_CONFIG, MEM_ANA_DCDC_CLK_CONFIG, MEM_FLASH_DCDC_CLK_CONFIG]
0x110 CM_SPARE — HIB1P2_CM_SPARE
  [31:24] CM_SPARE_OUT_M — HIB1P2_CM_SPARE
  [23:16] MEM_CM_TEST_CTRL_M — HIB1P2_CM_SPARE
  [15:0] MEM_CM_SPARE_M — HIB1P2_CM_SPARE
0x114 PORPOL_SPARE — HIB1P2_PORPOL_SPARE
  [31:0] MEM_PORPOL_SPARE_M
0x118 MEM_DIG_DCDC_CLK_CONFIG — HIB1P2_MEM_DIG_DCDC_CLK_CONFIG
  [8] MEM_DIG_DCDC_CLK_ENABLE — HIB1P2_MEM_DIG_DCDC_CLK_CONFIG
  [7:4] MEM_DIG_DCDC_CLK_PLLGEN_OFF_TIME_M — HIB1P2_MEM_DIG_DCDC_CLK_CONFIG
  [3:0] MEM_DIG_DCDC_CLK_PLLGEN_ON_TIME_M — HIB1P2_MEM_DIG_DCDC_CLK_CONFIG
0x11C MEM_ANA_DCDC_CLK_CONFIG — HIB1P2_MEM_ANA_DCDC_CLK_CONFIG
  [8] MEM_ANA_DCDC_CLK_ENABLE — HIB1P2_MEM_ANA_DCDC_CLK_CONFIG
  [7:4] MEM_ANA_DCDC_CLK_PLLGEN_OFF_TIME_M — HIB1P2_MEM_ANA_DCDC_CLK_CONFIG
  [3:0] MEM_ANA_DCDC_CLK_PLLGEN_ON_TIME_M — HIB1P2_MEM_ANA_DCDC_CLK_CONFIG
0x120 MEM_FLASH_DCDC_CLK_CONFIG — HIB1P2_MEM_FLASH_DCDC_CLK_CONFIG
  [8] MEM_FLASH_DCDC_CLK_ENABLE — HIB1P2_MEM_FLASH_DCDC_CLK_CONFIG
  [7:4] MEM_FLASH_DCDC_CLK_PLLGEN_OFF_TIME_M — HIB1P2_MEM_FLASH_DCDC_CLK_CONFIG
  [3:0] MEM_FLASH_DCDC_CLK_PLLGEN_ON_TIME_M — HIB1P2_MEM_FLASH_DCDC_CLK_CONFIG
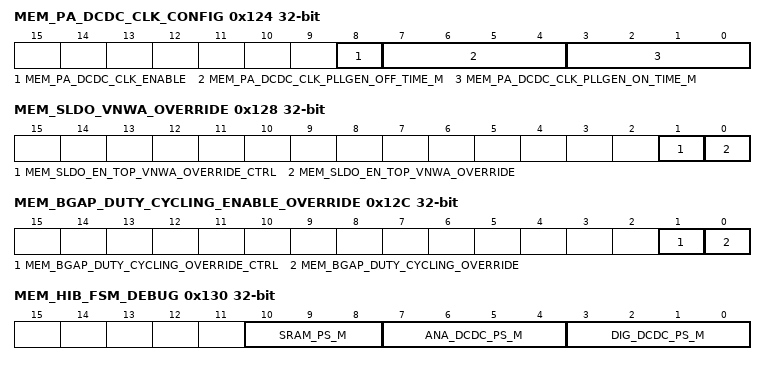
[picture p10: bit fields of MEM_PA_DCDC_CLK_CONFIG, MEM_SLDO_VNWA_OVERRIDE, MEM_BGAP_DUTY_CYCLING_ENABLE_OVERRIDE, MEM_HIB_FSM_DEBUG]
0x124 MEM_PA_DCDC_CLK_CONFIG — HIB1P2_MEM_PA_DCDC_CLK_CONFIG
  [8] MEM_PA_DCDC_CLK_ENABLE — HIB1P2_MEM_PA_DCDC_CLK_CONFIG
  [7:4] MEM_PA_DCDC_CLK_PLLGEN_OFF_TIME_M — HIB1P2_MEM_PA_DCDC_CLK_CONFIG
  [3:0] MEM_PA_DCDC_CLK_PLLGEN_ON_TIME_M — HIB1P2_MEM_PA_DCDC_CLK_CONFIG
0x128 MEM_SLDO_VNWA_OVERRIDE — HIB1P2_MEM_SLDO_VNWA_OVERRIDE
  [1] MEM_SLDO_EN_TOP_VNWA_OVERRIDE_CTRL — HIB1P2_MEM_SLDO_VNWA_OVERRIDE
  [0] MEM_SLDO_EN_TOP_VNWA_OVERRIDE — HIB1P2_MEM_SLDO_VNWA_OVERRIDE
0x12C MEM_BGAP_DUTY_CYCLING_ENABLE_OVERRIDE — HIB1P2_MEM_BGAP_DUTY_CYCLING_ENABLE_OVERRIDE
  [1] MEM_BGAP_DUTY_CYCLING_OVERRIDE_CTRL — HIB1P2_MEM_BGAP_DUTY_CYCLING_ENABLE_OVERRIDE
  [0] MEM_BGAP_DUTY_CYCLING_OVERRIDE — HIB1P2_MEM_BGAP_DUTY_CYCLING_ENABLE_OVERRIDE
0x130 MEM_HIB_FSM_DEBUG — HIB1P2_MEM_HIB_FSM_DEBUG
  [10:8] SRAM_PS_M — HIB1P2_MEM_HIB_FSM_DEBUG
  [7:4] ANA_DCDC_PS_M — HIB1P2_MEM_HIB_FSM_DEBUG
  [3:0] DIG_DCDC_PS_M — HIB1P2_MEM_HIB_FSM_DEBUG
0x134 MEM_SLDO_VNWA_SW_CTRL — HIB1P2_MEM_SLDO_VNWA_SW_CTRL
  [19:0] MEM_SLDO_VNWA_SW_CTRL_M
0x138 MEM_SLDO_WEAK_PROCESS — HIB1P2_MEM_SLDO_WEAK_PROCESS
  [0] MEM_SLDO_WEAK_PROCESS
0x13C MEM_PA_DCDC_OV_UV_STATUS — HIB1P2_MEM_PA_DCDC_OV_UV_STATUS
  [1] dcdc_pa_ov_prot_out_lowv
0x140 MEM_CM_TEST_MODE — HIB1P2_MEM_CM_TEST_MODE
  [0] mem_cm_test_mode
